# STM32H7x7_CM4 register map
File version: 1.0
CPU: CM4 r0p1, little endian, MPU, FPU, 4 interrupt priority bits
Registers are 32-bit, read-write, reset 0x0 unless marked. A register's access mark holds for its fields unless they carry their own. Offsets are from the block's base; [hi:lo] are bit positions; {n}, {i} and the like mark numbered series; 'fields as' and 'values as' point back to an identical list.

## CRYP — Cryptographic processor
Base 0x48021000
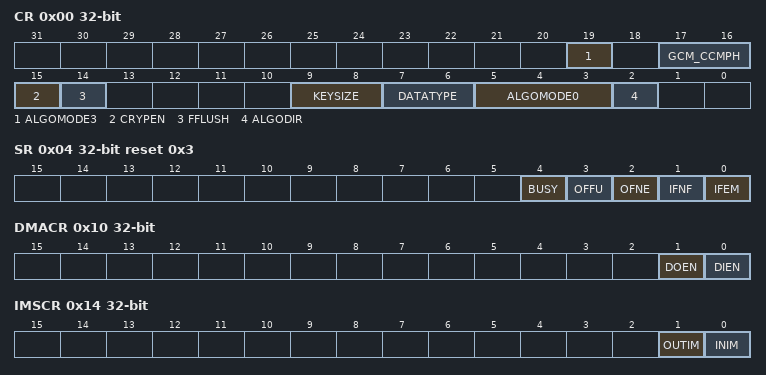
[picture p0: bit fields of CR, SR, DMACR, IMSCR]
0x00 CR access per field — control register
  [19] ALGOMODE3 rw — ALGOMODE
  [17:16] GCM_CCMPH rw
  [15] CRYPEN rw — Cryptographic processor enable
  [14] FFLUSH wo — FIFO flush
  [9:8] KEYSIZE rw — Key size selection (AES mode only)
  [7:6] DATATYPE rw — Data type selection
  [5:3] ALGOMODE0 rw — Algorithm mode
  [2] ALGODIR rw — Algorithm direction
0x04 SR ro reset 0x3 — status register
  [4] BUSY — Busy bit
  [3] OFFU — Output FIFO full
  [2] OFNE — Output FIFO not empty
  [1] IFNF — Input FIFO not full
  [0] IFEM — Input FIFO empty
0x08 DIN — data input register
  [31:0] DATAIN — Data input
0x0C DOUT ro — data output register
  [31:0] DATAOUT — Data output
0x10 DMACR — DMA control register
  [1] DOEN — DMA output enable
  [0] DIEN — DMA input enable
0x14 IMSCR — interrupt mask set/clear register
  [1] OUTIM — Output FIFO service interrupt mask
  [0] INIM — Input FIFO service interrupt mask
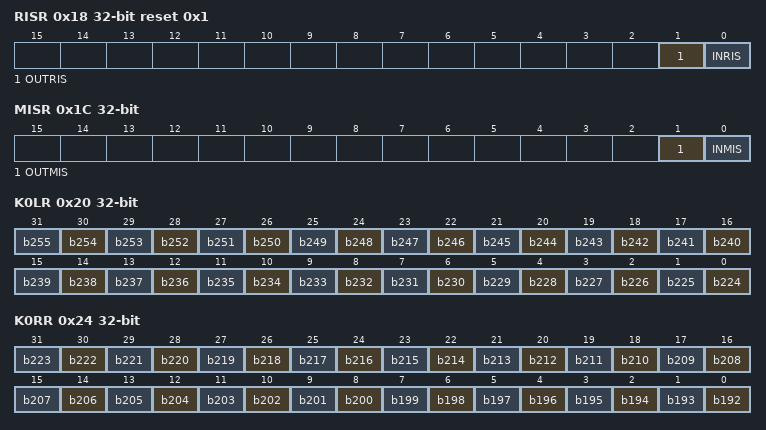
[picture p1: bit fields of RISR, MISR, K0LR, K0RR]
0x18 RISR ro reset 0x1 — raw interrupt status register
  [1] OUTRIS — Output FIFO service raw interrupt status
  [0] INRIS — Input FIFO service raw interrupt status
0x1C MISR ro — masked interrupt status register
  [1] OUTMIS — Output FIFO service masked interrupt status
  [0] INMIS — Input FIFO service masked interrupt status
0x20 K0LR wo — key registers
  [n-224] b{n} (n=224..255)
0x24 K0RR wo — key registers
  [n-192] b{n} (n=192..223)
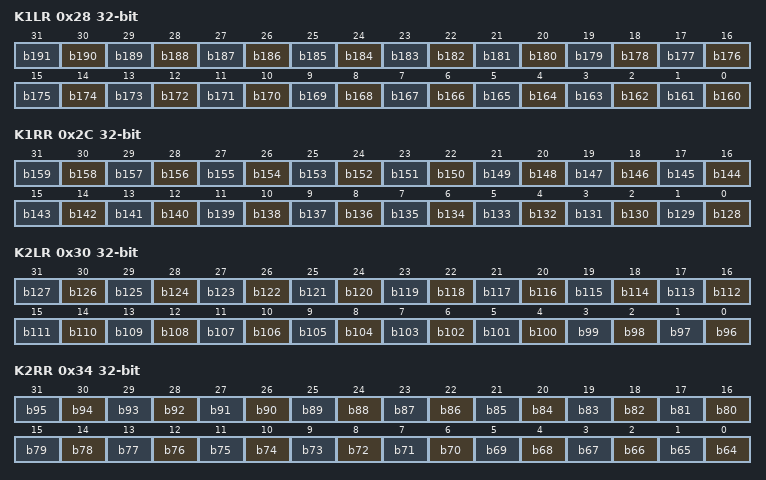
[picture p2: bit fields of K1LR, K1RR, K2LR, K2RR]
0x28 K1LR wo — key registers
  [n-160] b{n} (n=160..191)
0x2C K1RR wo — key registers
  [n-128] b{n} (n=128..159)
0x30 K2LR wo — key registers
  [n-96] b{n} (n=96..127)
0x34 K2RR wo — key registers
  [n-64] b{n} (n=64..95)
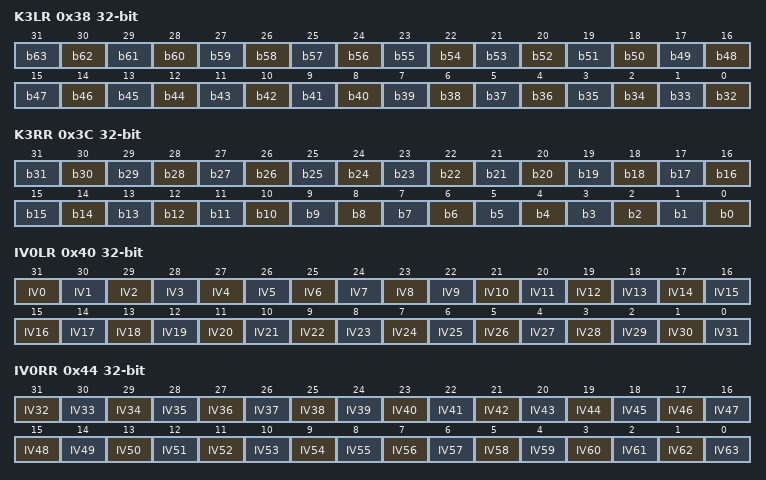
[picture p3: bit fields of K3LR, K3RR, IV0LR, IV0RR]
0x38 K3LR wo — key registers
  [n-32] b{n} (n=32..63)
0x3C K3RR wo — key registers
  [n] b{n} (n=0..31)
0x40 IV0LR — initialization vector registers
  [31-n] IV{n} (n=0..31)
0x44 IV0RR — initialization vector registers
  [63-n] IV{n} (n=32..63)
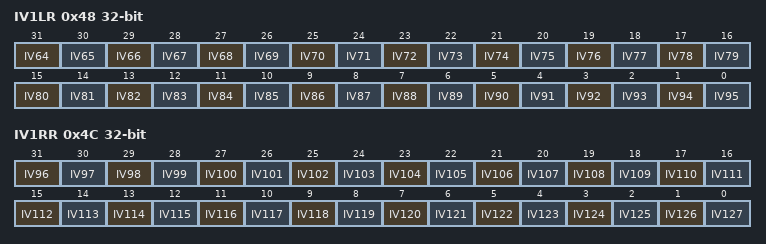
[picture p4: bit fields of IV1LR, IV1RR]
0x48 IV1LR — initialization vector registers
  [95-n] IV{n} (n=64..95)
0x4C IV1RR — initialization vector registers
  [127-n] IV{n} (n=96..127)
{0x50+4i} CSGCMCCM{i}R (i=0..7) — context swap register
{0x70+4i} CSGCM{i}R (i=0..7) — context swap register

## OPAMP — Operational amplifiers
Base 0x40009000
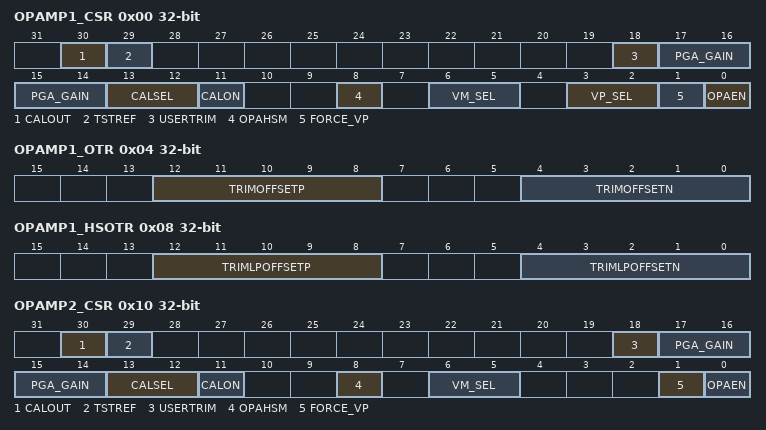
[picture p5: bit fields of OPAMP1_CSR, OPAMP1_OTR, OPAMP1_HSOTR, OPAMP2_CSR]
0x00 OPAMP1_CSR access per field — OPAMP1 control/status register
  [30] CALOUT ro — Operational amplifier calibration output
  [29] TSTREF rw — OPAMP calibration reference voltage output control (reserved for test)
  [18] USERTRIM rw — User trimming enable
  [17:14] PGA_GAIN rw — allows to switch from AOP offset trimmed values to AOP offset
  [13:12] CALSEL rw — Calibration selection
  [11] CALON rw — Calibration mode enabled
  [8] OPAHSM rw — Operational amplifier high-speed mode
  [6:5] VM_SEL rw — Inverting input selection
  [3:2] VP_SEL rw — Operational amplifier PGA mode
  [1] FORCE_VP rw — Force internal reference on VP (reserved for test
  [0] OPAEN rw — Operational amplifier Enable
0x04 OPAMP1_OTR — OPAMP1 offset trimming register in normal mode
  [12:8] TRIMOFFSETP — Trim for PMOS differential pairs
  [4:0] TRIMOFFSETN — Trim for NMOS differential pairs
0x08 OPAMP1_HSOTR — OPAMP1 offset trimming register in low-power mode
  [12:8] TRIMLPOFFSETP — Trim for PMOS differential pairs
  [4:0] TRIMLPOFFSETN — Trim for NMOS differential pairs
0x10 OPAMP2_CSR access per field — OPAMP2 control/status register
  [30] CALOUT ro — Operational amplifier calibration output
  [29] TSTREF rw — OPAMP calibration reference voltage output control (reserved for test)
  [18] USERTRIM rw — User trimming enable
  [17:14] PGA_GAIN rw — Operational amplifier Programmable amplifier gain value
  [13:12] CALSEL rw — Calibration selection
  [11] CALON rw — Calibration mode enabled
  [8] OPAHSM rw — Operational amplifier high-speed mode
  [6:5] VM_SEL rw — Inverting input selection
  [1] FORCE_VP rw — Force internal reference on VP (reserved for test)
  [0] OPAEN rw — Operational amplifier Enable
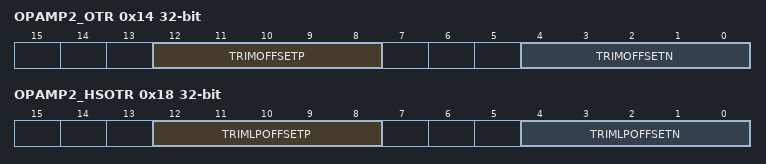
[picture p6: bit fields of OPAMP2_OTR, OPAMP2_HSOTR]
0x14 OPAMP2_OTR — OPAMP2 offset trimming register in normal mode
  fields as OPAMP1_OTR
0x18 OPAMP2_HSOTR — OPAMP2 offset trimming register in low-power mode
  fields as OPAMP1_HSOTR
